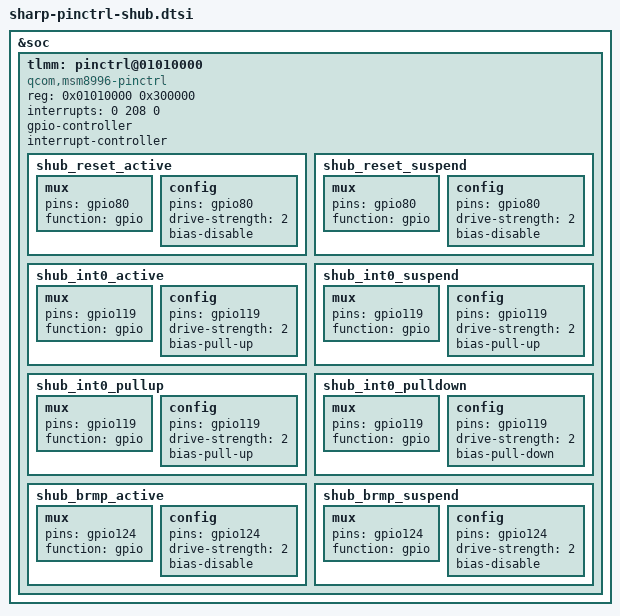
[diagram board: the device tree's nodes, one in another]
/* Copyright (c) 2013-2014, The Linux Foundation. All rights reserved.
 *
 * This program is free software; you can redistribute it and/or modify
 * it under the terms of the GNU General Public License version 2 and
 * only version 2 as published by the Free Software Foundation.
 *
 * This program is distributed in the hope that it will be useful,
 * but WITHOUT ANY WARRANTY; without even the implied warranty of
 * MERCHANTABILITY or FITNESS FOR A PARTICULAR PURPOSE.  See the
 * GNU General Public License for more details.
 */

&soc {
	tlmm: pinctrl@01010000 {
		compatible = "qcom,msm8996-pinctrl";
		reg = <0x01010000 0x300000>;
		interrupts = <0 208 0>;
		gpio-controller;
		interrupt-controller;

		/*****************************************/
		/*  pinctrl customize setting            */
		/*  SensorHub                            */
		/*****************************************/
		shub_reset_active: shub_reset_active {
			mux {
				pins = "gpio80";
				function = "gpio";
			};
			config {
				pins = "gpio80";
				drive-strength = <2>;
				bias-disable;
			};
		};
		shub_reset_suspend: shub_reset_suspend {
			mux {
				pins = "gpio80";
				function = "gpio";
			};
			config {
				pins = "gpio80";
				drive-strength = <2>;
				bias-disable;
			};
		};

		shub_int0_active: shub_int0_active {
			mux {
				pins = "gpio119";
				function = "gpio";
			};
			config {
				pins = "gpio119";
				drive-strength = <2>;
				bias-pull-up;
			};
		};
		shub_int0_suspend: shub_int0_suspend {
			mux {
				pins = "gpio119";
				function = "gpio";
			};
			config {
				pins = "gpio119";
				drive-strength = <2>;
				bias-pull-up;
			};
		};
		shub_int0_pullup: shub_int0_pullup {
			mux {
				pins = "gpio119";
				function = "gpio";
			};
			config {
				pins = "gpio119";
				drive-strength = <2>;
				bias-pull-up;
			};
		};
		shub_int0_pulldown: shub_int0_pulldown {
			mux {
				pins = "gpio119";
				function = "gpio";
			};
			config {
				pins = "gpio119";
				drive-strength = <2>;
				bias-pull-down;
			};
		};

		shub_brmp_active: shub_brmp_active {
			mux {
				pins = "gpio124";
				function = "gpio";
			};
			config {
				pins = "gpio124";
				drive-strength = <2>;
				bias-disable;
			};
		};
		shub_brmp_suspend: shub_brmp_suspend {
			mux {
				pins = "gpio124";
				function = "gpio";
			};
			config {
				pins = "gpio124";
				drive-strength = <2>;
				bias-disable;
			};
		};
	};
};
